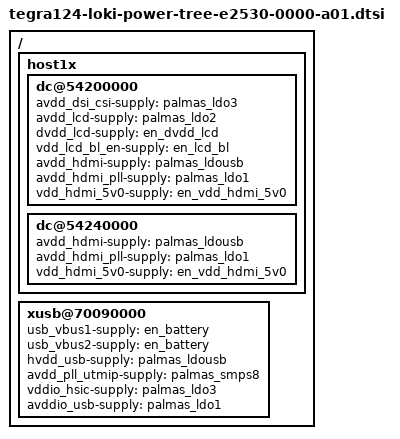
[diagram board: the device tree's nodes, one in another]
/*
 * Copyright (c) 2014, NVIDIA CORPORATION.  All rights reserved.
 *
 * This program is free software; you can redistribute it and/or modify it
 * under the terms and conditions of the GNU General Public License,
 * version 2, as published by the Free Software Foundation.
 *
 * This program is distributed in the hope it will be useful, but WITHOUT
 * ANY WARRANTY; without even the implied warranty of MERCHANTABILITY or
 * FITNESS FOR A PARTICULAR PURPOSE.  See the GNU General Public License for
 * more details.
 */

#include "tegra124-platforms/tegra124-loki-pmic-e2530-0000-a01.dtsi"
#include "tegra124-platforms/tegra124-loki-fixed-e2530-0000-a00.dtsi"

/ {
	host1x {
		/* tegradc.0 */
		dc@54200000 {
			avdd_dsi_csi-supply = <&palmas_ldo3>;
			avdd_lcd-supply = <&palmas_ldo2>;
			dvdd_lcd-supply = <&en_dvdd_lcd>;
			vdd_lcd_bl_en-supply = <&en_lcd_bl>;
			avdd_hdmi-supply = <&palmas_ldousb>;
			avdd_hdmi_pll-supply = <&palmas_ldo1>;
			vdd_hdmi_5v0-supply = <&en_vdd_hdmi_5v0>;
		};
		/* tegradc.1 */
		dc@54240000 {
			avdd_hdmi-supply = <&palmas_ldousb>;
			avdd_hdmi_pll-supply = <&palmas_ldo1>;
			vdd_hdmi_5v0-supply = <&en_vdd_hdmi_5v0>;
		};
	};
	xusb@70090000 {
		usb_vbus1-supply = <&en_battery>;
		usb_vbus2-supply = <&en_battery>;
		hvdd_usb-supply = <&palmas_ldousb>;
		avdd_pll_utmip-supply = <&palmas_smps8>;
		vddio_hsic-supply = <&palmas_ldo3>;
		avddio_usb-supply = <&palmas_ldo1>;
	};
};
